AUTOSAR XML (schema 00049)
package /ARRoot
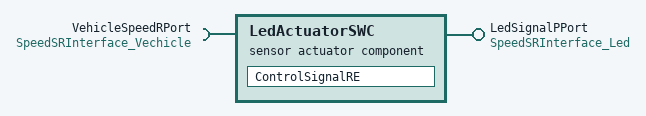
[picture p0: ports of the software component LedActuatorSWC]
  sensor actuator sw component type LedActuatorSWC
    provide port LedSignalPPort: provided-interface=SpeedSRInterface_Led
    require port VehicleSpeedRPort: required-interface=SpeedSRInterface_Vechicle
    behavior LedActuatorInternalBehaviour
      runnable ControlSignalRE: variable-access=accessed-variable=VechicleSpeed, variable-access=accessed-variable=LedSignal
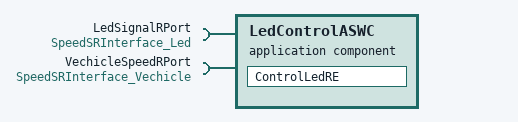
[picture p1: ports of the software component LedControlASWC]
  application sw component type LedControlASWC
    require port LedSignalRPort: required-interface=SpeedSRInterface_Led
    require port VechicleSpeedRPort: required-interface=SpeedSRInterface_Vechicle
    behavior LedControlInternalBehaviour
      runnable ControlLedRE: variable-access=accessed-variable=VechicleSpeed
  client server interface SpeedCSInterface
    operation GetSpeed
  composition sw component type SpeedComposition
    4 x component:
      LedActuatorComponentPrototype: type=LedActuatorSWC
      LedControlComponentPrototype: type=LedControlASWC
      VechicleSpeedSwComponentPrototype: type=VechicleSpeedASWC
      WheelSpeedSwComponentPrototype: type=WheelSpeedASWC
    connect LedActuatorComponentPrototype.LedSignalPPort -> LedControlComponentPrototype.LedSignalRPort
    connect VechicleSpeedSwComponentPrototype.VechicleSpeedPPort -> LedControlComponentPrototype.VechicleSpeedRPort
    connect VechicleSpeedSwComponentPrototype.VechicleSpeedPPort -> LedActuatorComponentPrototype.VehicleSpeedRPort
    connect WheelSpeedSwComponentPrototype.WheelSpeedPPort -> VechicleSpeedSwComponentPrototype.WheelSpeedRPort
  sender receiver interface SpeedSRInterface_Led
    data LedSignal: type=uint16
  sender receiver interface SpeedSRInterface_Vechicle
    data VechicleSpeed: type=uint16
  sender receiver interface SpeedSRInterface_Wheel
    data WheelSpeed: type=uint16
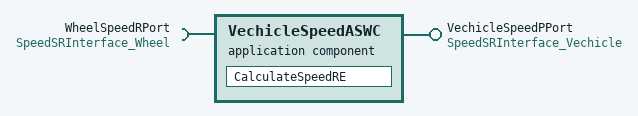
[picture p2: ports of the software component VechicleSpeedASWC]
  application sw component type VechicleSpeedASWC
    provide port VechicleSpeedPPort: provided-interface=SpeedSRInterface_Vechicle
    require port WheelSpeedRPort: required-interface=SpeedSRInterface_Wheel
    behavior VechicleSpeedInternalBehaviour
      runnable CalculateSpeedRE: variable-access=accessed-variable=WheelSpeed, variable-access=accessed-variable=VechicleSpeed
  ecu abstraction sw component type WheelEcuAbstractionSWC
    provide port ADCPPort: provided-interface=SpeedSRInterface_Wheel
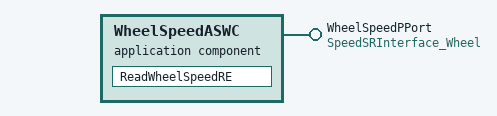
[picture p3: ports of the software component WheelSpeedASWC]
  application sw component type WheelSpeedASWC
    provide port WheelSpeedPPort: provided-interface=SpeedSRInterface_Wheel
    behavior WheelSpeedInternalBehaviour
      runnable ReadWheelSpeedRE: variable-access=accessed-variable=WheelSpeed
  app type uint16
